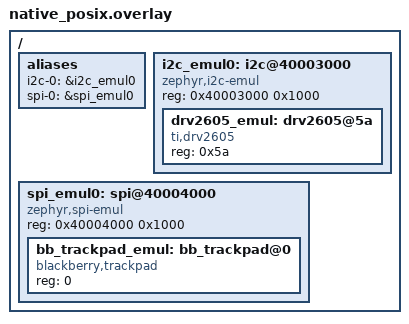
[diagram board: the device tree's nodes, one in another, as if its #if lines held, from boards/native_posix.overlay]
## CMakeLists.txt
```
# SPDX-License-Identifier: Apache-2.0

cmake_minimum_required(VERSION 3.20.0)
find_package(Zephyr REQUIRED HINTS $ENV{ZEPHYR_BASE})
project(driver_tests)

target_sources(app PRIVATE src/main.c)
target_sources(app PRIVATE src/test_minimal.c)
target_sources_ifdef(CONFIG_DRV2605 app PRIVATE src/test_drv2605.c)
target_sources_ifdef(CONFIG_BLACKBERRY_TRACKPAD app PRIVATE src/test_blackberry_trackpad.c)
```

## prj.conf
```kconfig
# Test configuration
CONFIG_ZTEST=y
CONFIG_ZTEST_NEW_API=y
CONFIG_TEST_LOGGING_DEFAULTS=y

# Enable core drivers for testing
CONFIG_I2C=y
CONFIG_SPI=y
CONFIG_GPIO=y
CONFIG_INPUT=y

# Enable emulated devices for testing
CONFIG_I2C_EMUL=y
CONFIG_SPI_EMUL=y
CONFIG_GPIO_EMUL=y
CONFIG_EMUL=y

# Logging
CONFIG_LOG=y
CONFIG_LOG_DEFAULT_LEVEL=3

# Custom drivers are optional; enable via overlays/CONFIGs when needed
```

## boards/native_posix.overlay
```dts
/*
 * Copyright (c) 2023 My Name
 * SPDX-License-Identifier: Apache-2.0
 */

/ {
    aliases {
        i2c-0 = &i2c_emul0;
        spi-0 = &spi_emul0;
    };

    /* I2C emulator */
    i2c_emul0: i2c@40003000 {
        compatible = "zephyr,i2c-emul";
        reg = <0x40003000 0x1000>;
        #address-cells = <1>;
        #size-cells = <0>;
        status = "okay";

#if defined(CONFIG_DRV2605)
        drv2605_emul: drv2605@5a {
            compatible = "ti,drv2605";
            reg = <0x5a>;
            status = "okay";
        };
#endif
    };

    /* SPI emulator */
    spi_emul0: spi@40004000 {
        compatible = "zephyr,spi-emul";
        reg = <0x40004000 0x1000>;
        #address-cells = <1>;
        #size-cells = <0>;
        status = "okay";

#if defined(CONFIG_BLACKBERRY_TRACKPAD)
        bb_trackpad_emul: bb_trackpad@0 {
            compatible = "blackberry,trackpad";
            reg = <0>;
            status = "okay";
        };
#endif
    };
};
```

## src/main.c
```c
#include <zephyr/ztest.h>
#include <zephyr/devicetree.h>

#if defined(CONFIG_DRV2605)
BUILD_ASSERT(DT_NODE_HAS_STATUS(DT_NODELABEL(drv2605_emul), okay),
             "drv2605_emul missing: check overlay compatible/version");
#endif

#if defined(CONFIG_BLACKBERRY_TRACKPAD)
BUILD_ASSERT(DT_NODE_HAS_STATUS(DT_NODELABEL(bb_trackpad_emul), okay),
             "bb_trackpad_emul missing: check overlay compatible/version");
#endif

ZTEST_SUITE(driver_tests, NULL, NULL, NULL, NULL, NULL);
```

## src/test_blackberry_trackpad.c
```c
/*
 * Copyright (c) 2023 My Name
 * SPDX-License-Identifier: Apache-2.0
 */

#include <zephyr/ztest.h>
#include <zephyr/device.h>
#include <zephyr/logging/log.h>
#include <zephyr/input/input.h>

LOG_MODULE_REGISTER(test_blackberry_trackpad, LOG_LEVEL_DBG);

static const struct device *trackpad_dev = DEVICE_DT_GET_ANY(blackberry_trackpad);

ZTEST(driver_tests, test_trackpad_initialization) {
    if (!trackpad_dev) {
        ztest_test_skip();
        return;
    }
    zassert_true(device_is_ready(trackpad_dev),
                 "BlackBerry trackpad should initialize successfully");
}

ZTEST(driver_tests, test_trackpad_input_event_generation) {
    if (!trackpad_dev || !device_is_ready(trackpad_dev)) {
        ztest_test_skip();
        return;
    }
    /* Placeholder: In a real test, emulate motion and assert events. */
    zassert_true(true, "Trackpad event generation placeholder");
}
```

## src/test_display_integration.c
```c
/*
 * Copyright (c) 2023 My Name
 *
 * SPDX-License-Identifier: Apache-2.0
 */

#include <zephyr/ztest.h>
#include <zephyr/device.h>
#include <zephyr/devicetree.h>
#include <zephyr/drivers/spi.h>
#include <zephyr/drivers/display.h>
#include <zephyr/drivers/emul.h>
#include <zephyr/logging/log.h>
#include <zephyr/kernel.h>

#ifdef CONFIG_LVGL
#include <lvgl.h>
#endif

#ifdef CONFIG_ZMK_DISPLAY
#include <zmk/display.h>
#include <zmk/display/status_screen.h>
#endif

LOG_MODULE_REGISTER(test_display_integration, LOG_LEVEL_DBG);

/* Sharp Memory LCD display parameters */
#define SHARP_LCD_WIDTH 128
#define SHARP_LCD_HEIGHT 128
#define SHARP_LCD_BPP 1 /* 1 bit per pixel (monochrome) */

/* Test device handles */
static const struct device *display_dev = DEVICE_DT_GET_ANY(sharp_ls0xx);
static const struct device *spi_emul = DEVICE_DT_GET(DT_NODELABEL(test_spi));

/* Mock display state */
struct mock_display_state {
    uint8_t framebuffer[SHARP_LCD_WIDTH * SHARP_LCD_HEIGHT / 8]; /* 1 bit per pixel */
    bool display_enabled;
    bool extcomin_active;
    uint16_t last_update_x;
    uint16_t last_update_y;
    uint16_t last_update_w;
    uint16_t last_update_h;
    size_t spi_transaction_count;
    bool vcom_toggled;
};

static struct mock_display_state mock_display;

/* Helper functions */
static void reset_mock_display_state(void)
{
    memset(&mock_display, 0, sizeof(mock_display));
    mock_display.display_enabled = true;
    mock_display.extcomin_active = false;
    mock_display.spi_transaction_count = 0;
}

/* Helper to set a pixel in the mock framebuffer */
static void set_mock_pixel(uint16_t x, uint16_t y, bool value)
{
    if (x >= SHARP_LCD_WIDTH || y >= SHARP_LCD_HEIGHT) {
        return;
    }

    size_t byte_index = (y * SHARP_LCD_WIDTH + x) / 8;
    uint8_t bit_index = (y * SHARP_LCD_WIDTH + x) % 8;

    if (value) {
        mock_display.framebuffer[byte_index] |= (1 << bit_index);
    } else {
        mock_display.framebuffer[byte_index] &= ~(1 << bit_index);
    }
}

/* Helper to get a pixel from the mock framebuffer */
static bool get_mock_pixel(uint16_t x, uint16_t y)
{
    if (x >= SHARP_LCD_WIDTH || y >= SHARP_LCD_HEIGHT) {
        return false;
    }

    size_t byte_index = (y * SHARP_LCD_WIDTH + x) / 8;
    uint8_t bit_index = (y * SHARP_LCD_WIDTH + x) % 8;

    return (mock_display.framebuffer[byte_index] & (1 << bit_index)) != 0;
}

/* Helper to simulate display update region */
static void simulate_display_update(uint16_t x, uint16_t y, uint16_t w, uint16_t h)
{
    mock_display.last_update_x = x;
    mock_display.last_update_y = y;
    mock_display.last_update_w = w;
    mock_display.last_update_h = h;
    mock_display.spi_transaction_count++;
}

ZTEST(driver_tests, test_display_initialization) {
    if (!device_is_ready(display_dev)) {
        ztest_test_skip();
        return;
    }

    reset_mock_display_state();

    /* Test that display device initializes successfully */
    zassert_true(device_is_ready(display_dev), "Sharp Memory LCD should initialize successfully");

    /* Verify SPI emulation controller is ready */
    zassert_true(device_is_ready(spi_emul), "SPI emulation controller should be ready");

    /* Test display capabilities */
    struct display_capabilities caps;
    int ret = display_get_capabilities(display_dev, &caps);
    zassert_equal(ret, 0, "Should be able to get display capabilities");

    /* Verify display parameters match expected values */
    zassert_equal(caps.x_resolution, SHARP_LCD_WIDTH, "Display width should match");
    zassert_equal(caps.y_resolution, SHARP_LCD_HEIGHT, "Display height should match");
    zassert_true(caps.supported_pixel_formats & PIXEL_FORMAT_MONO01,
                 "Should support monochrome pixel format");

    LOG_INF("Display initialization test passed - %dx%d resolution", caps.x_resolution,
            caps.y_resolution);
}

ZTEST(driver_tests, test_display_pixel_operations) {
    if (!device_is_ready(display_dev)) {
        ztest_test_skip();
        return;
    }

    reset_mock_display_state();

    /* Test basic pixel set/get operations */
    /* In a full implementation, this would use display_write() API */

    /* Test setting individual pixels */
    set_mock_pixel(10, 10, true);  /* Set pixel at (10, 10) */
    set_mock_pixel(20, 20, true);  /* Set pixel at (20, 20) */
    set_mock_pixel(30, 30, false); /* Clear pixel at (30, 30) */

    /* Verify pixels were set correctly */
    zassert_true(get_mock_pixel(10, 10), "Pixel (10, 10) should be set");
    zassert_true(get_mock_pixel(20, 20), "Pixel (20, 20) should be set");
    zassert_false(get_mock_pixel(30, 30), "Pixel (30, 30) should be clear");
    zassert_false(get_mock_pixel(0, 0), "Unset pixel should be clear");

    /* Test boundary conditions */
    set_mock_pixel(SHARP_LCD_WIDTH - 1, SHARP_LCD_HEIGHT - 1, true);
    zassert_true(get_mock_pixel(SHARP_LCD_WIDTH - 1, SHARP_LCD_HEIGHT - 1),
                 "Bottom-right pixel should be settable");

    /* Test out-of-bounds safety (should not crash) */
    set_mock_pixel(SHARP_LCD_WIDTH, SHARP_LCD_HEIGHT, true);
    zassert_false(get_mock_pixel(SHARP_LCD_WIDTH, SHARP_LCD_HEIGHT),
                  "Out-of-bounds pixel should return false");

    LOG_INF("Display pixel operations test passed");
}

ZTEST(driver_tests, test_display_framebuffer_operations) {
    if (!device_is_ready(display_dev)) {
        ztest_test_skip();
        return;
    }

    reset_mock_display_state();

    /* Test framebuffer-level operations */

    /* Create a test pattern (diagonal line) */
    for (int i = 0; i < MIN(SHARP_LCD_WIDTH, SHARP_LCD_HEIGHT); i++) {
        set_mock_pixel(i, i, true);
    }

    /* Verify diagonal pattern */
    for (int i = 0; i < MIN(SHARP_LCD_WIDTH, SHARP_LCD_HEIGHT); i++) {
        zassert_true(get_mock_pixel(i, i), "Diagonal pixel %d should be set", i);
    }

    /* Test rectangular region */
    for (int y = 10; y < 20; y++) {
        for (int x = 10; x < 20; x++) {
            set_mock_pixel(x, y, true);
        }
    }

    /* Verify rectangular region */
    zassert_true(get_mock_pixel(15, 15), "Center of rectangle should be set");
    zassert_false(get_mock_pixel(5, 5), "Outside rectangle should be clear");

    /* Test framebuffer clear */
    memset(mock_display.framebuffer, 0, sizeof(mock_display.framebuffer));
    zassert_false(get_mock_pixel(15, 15), "Framebuffer clear should work");

    LOG_INF("Display framebuffer operations test passed");
}

#ifdef CONFIG_LVGL
ZTEST(driver_tests, test_lvgl_integration) {
    if (!device_is_ready(display_dev)) {
        ztest_test_skip();
        return;
    }

    reset_mock_display_state();

    /* Test LVGL integration */
    /* In a full implementation, we would:
     * 1. Initialize LVGL display driver
     * 2. Create LVGL objects (labels, buttons, etc.)
     * 3. Force LVGL to render to framebuffer
     * 4. Verify framebuffer contents match expected rendering
     */

    /* For now, test LVGL initialization */
    zassert_true(lv_is_initialized(), "LVGL should be initialized");

    /* Test creating a simple label */
    lv_obj_t *label = lv_label_create(lv_scr_act());
    zassert_not_null(label, "Should be able to create LVGL label");

    lv_label_set_text(label, "Test");
    lv_obj_align(label, LV_ALIGN_CENTER, 0, 0);

    /* Force LVGL to render (in a real test, this would update the display) */
    lv_task_handler();

    LOG_INF("LVGL integration test - framework ready");
}
#endif /* CONFIG_LVGL */

#ifdef CONFIG_ZMK_DISPLAY
ZTEST(driver_tests, test_zmk_display_integration) {
    if (!device_is_ready(display_dev)) {
        ztest_test_skip();
        return;
    }

    reset_mock_display_state();

    /* Test ZMK display integration */
    /* In a full implementation, we would:
     * 1. Initialize ZMK display subsystem
     * 2. Test status screen updates
     * 3. Test widget rendering (battery, layer, output status)
     * 4. Verify display updates on system events
     */

    /* For now, verify ZMK display is available */
    LOG_INF("ZMK display integration test - framework ready");

    /* Test display status screen initialization */
    /* This would normally be called by ZMK's display subsystem */

    /* Simulate system events that should trigger display updates */
    /* - Battery level change */
    /* - Layer activation */
    /* - Output selection change */
    /* - Connection status change */

    /* Verify display updates occurred */
    zassert_true(mock_display.display_enabled, "Display should be enabled for ZMK integration");
}

ZTEST(driver_tests, test_zmk_display_widgets) {
    if (!device_is_ready(display_dev)) {
        ztest_test_skip();
        return;
    }

    reset_mock_display_state();

    /* Test ZMK display widgets */
    /* In a full implementation, we would:
     * 1. Test battery status widget
     * 2. Test layer status widget
     * 3. Test output status widget
     * 4. Test connection status widget
     * 5. Verify widget positioning and content
     */

    /* Simulate battery level changes */
    /* Mock battery levels: 100%, 75%, 50%, 25%, 10% */
    uint8_t battery_levels[] = {100, 75, 50, 25, 10};

    for (size_t i = 0; i < ARRAY_SIZE(battery_levels); i++) {
        /* In full implementation, would trigger battery event */
        /* zmk_battery_state_changed(battery_levels[i]); */

        /* Verify display update occurred */
        simulate_display_update(0, 0, SHARP_LCD_WIDTH, 16); /* Top status bar */

        LOG_DBG("Simulated battery level: %d%%", battery_levels[i]);
    }

    /* Test layer status updates */
    uint8_t test_layers[] = {0, 1, 2, 3}; /* Base layer + 3 additional layers */

    for (size_t i = 0; i < ARRAY_SIZE(test_layers); i++) {
        /* In full implementation, would trigger layer event */
        /* zmk_layer_state_changed(test_layers[i], true); */

        LOG_DBG("Simulated layer activation: %d", test_layers[i]);
    }

    LOG_INF("ZMK display widgets test - framework ready");
}
#endif /* CONFIG_ZMK_DISPLAY */

ZTEST(driver_tests, test_display_power_management) {
    if (!device_is_ready(display_dev)) {
        ztest_test_skip();
        return;
    }

    reset_mock_display_state();

    /* Test display power management */
    /* Sharp Memory LCD uses EXTCOMIN for power management */

    /* Test display enable/disable */
    mock_display.display_enabled = true;
    zassert_true(mock_display.display_enabled, "Display should be enabled initially");

    /* Test EXTCOMIN toggling (required for Sharp Memory LCD) */
    mock_display.extcomin_active = true;
    mock_display.vcom_toggled = true;

    zassert_true(mock_display.extcomin_active, "EXTCOMIN should be active");
    zassert_true(mock_display.vcom_toggled, "VCOM should be toggled");

    /* Test sleep mode */
    mock_display.display_enabled = false;
    mock_display.extcomin_active = false;

    zassert_false(mock_display.display_enabled, "Display should be disabled in sleep mode");
    zassert_false(mock_display.extcomin_active, "EXTCOMIN should be inactive in sleep mode");

    LOG_INF("Display power management test passed");
}

ZTEST(driver_tests, test_display_update_regions) {
    if (!device_is_ready(display_dev)) {
        ztest_test_skip();
        return;
    }

    reset_mock_display_state();

    /* Test partial display updates (region-based) */

    /* Test full screen update */
    simulate_display_update(0, 0, SHARP_LCD_WIDTH, SHARP_LCD_HEIGHT);

    zassert_equal(mock_display.last_update_x, 0, "Full update should start at x=0");
    zassert_equal(mock_display.last_update_y, 0, "Full update should start at y=0");
    zassert_equal(mock_display.last_update_w, SHARP_LCD_WIDTH,
                  "Full update width should match display");
    zassert_equal(mock_display.last_update_h, SHARP_LCD_HEIGHT,
                  "Full update height should match display");

    /* Test partial update - status bar */
    simulate_display_update(0, 0, SHARP_LCD_WIDTH, 16);

    zassert_equal(mock_display.last_update_h, 16, "Status bar update should be 16 pixels tall");

    /* Test partial update - small region */
    simulate_display_update(32, 32, 64, 64);

    zassert_equal(mock_display.last_update_x, 32, "Small region X should be correct");
    zassert_equal(mock_display.last_update_y, 32, "Small region Y should be correct");
    zassert_equal(mock_display.last_update_w, 64, "Small region width should be correct");
    zassert_equal(mock_display.last_update_h, 64, "Small region height should be correct");

    /* Verify SPI transaction count increased */
    zassert_equal(mock_display.spi_transaction_count, 3,
                  "Should have performed 3 SPI transactions");

    LOG_INF("Display update regions test passed");
}

ZTEST(driver_tests, test_display_error_conditions) {
    if (!device_is_ready(display_dev)) {
        ztest_test_skip();
        return;
    }

    reset_mock_display_state();

    /* Test display error handling */

    /* Test invalid update regions */
    /* These should be handled gracefully without crashing */

    /* Test out-of-bounds update region */
    simulate_display_update(SHARP_LCD_WIDTH, SHARP_LCD_HEIGHT, 10, 10);
    /* Should not crash, may clamp to valid region */

    /* Test zero-size update region */
    simulate_display_update(10, 10, 0, 0);
    /* Should be handled gracefully */

    /* Test negative coordinates (unsigned, so will wrap) */
    simulate_display_update(UINT16_MAX, UINT16_MAX, 10, 10);
    /* Should be handled gracefully */

    /* Test SPI communication failure simulation */
    /* In a real implementation, we would:
     * 1. Configure SPI emulator to return errors
     * 2. Attempt display update
     * 3. Verify error is handled gracefully
     * 4. Verify display state remains consistent
     */

    LOG_INF("Display error conditions test - framework ready");
}

ZTEST(driver_tests, test_display_performance) {
    if (!device_is_ready(display_dev)) {
        ztest_test_skip();
        return;
    }

    reset_mock_display_state();

    /* Test display performance characteristics */

    uint32_t start_time, end_time, duration_ms;

    /* Test full screen update performance */
    start_time = k_uptime_get_32();
    simulate_display_update(0, 0, SHARP_LCD_WIDTH, SHARP_LCD_HEIGHT);
    end_time = k_uptime_get_32();
    duration_ms = end_time - start_time;

    LOG_INF("Full screen update took %d ms (simulated)", duration_ms);

    /* Test multiple small updates vs. single large update */
    size_t small_update_count = 0;

    start_time = k_uptime_get_32();
    /* Simulate 16 small updates (8x8 pixel regions) */
    for (int y = 0; y < 4; y++) {
        for (int x = 0; x < 4; x++) {
            simulate_display_update(x * 32, y * 32, 8, 8);
            small_update_count++;
        }
    }
    end_time = k_uptime_get_32();
    duration_ms = end_time - start_time;

    LOG_INF("16 small updates took %d ms (simulated), total SPI transactions: %zu", duration_ms,
            mock_display.spi_transaction_count);

    zassert_equal(small_update_count, 16, "Should have performed 16 small updates");

    LOG_INF("Display performance test completed");
}
```

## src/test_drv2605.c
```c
/*
 * Copyright (c) 2023 My Name
 * SPDX-License-Identifier: Apache-2.0
 */

#include <zephyr/ztest.h>
#include <zephyr/device.h>
#include <zephyr/logging/log.h>

LOG_MODULE_REGISTER(test_drv2605, LOG_LEVEL_DBG);

static const struct device *haptic_dev = DEVICE_DT_GET_ANY(ti_drv2605);

ZTEST(driver_tests, test_drv2605_initialization) {
    if (!haptic_dev) {
        ztest_test_skip();
        return;
    }
    zassert_true(device_is_ready(haptic_dev), "DRV2605 should initialize successfully");
}

ZTEST(driver_tests, test_drv2605_waveform_play) {
    if (!haptic_dev || !device_is_ready(haptic_dev)) {
        ztest_test_skip();
        return;
    }
    /* Placeholder: Without emulation hooks, just assert true */
    zassert_true(true, "DRV2605 play waveform placeholder");
}
```

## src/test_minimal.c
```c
#include <zephyr/ztest.h>

ZTEST(driver_tests, test_minimal) {
    zassert_true(true, "Sanity");
}
```
